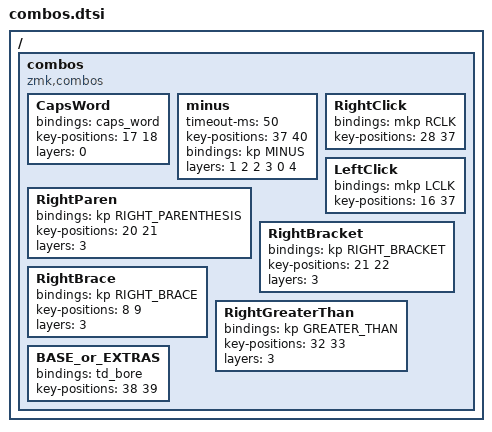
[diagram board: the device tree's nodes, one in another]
// ╭──────┬──────┬──────┬──────┬──────┬──────╮  ╭──────┬──────┬──────┬──────┬──────┬──────╮
//    00     01     02     03    04      05        06     07     08     09     10     11
// ├──────┼──────┼──────┼──────┼──────┼──────┤  ├──────┼──────┼──────┼──────┼──────┼──────┤
//    12     13     14     15    16      17        18     19     20     21     22     23
// ├──────┼──────┼──────┼──────┼──────┼──────┤  ├──────┼──────┼──────┼──────┼──────┼──────┤
//    24     25     26     27    28      29        30     31     32     33     34     35
// ╰──────┴──────┴──────┼──────┼──────┼──────┤  ├──────┼──────┼──────┴──────┴──────┴──────╯
//                         36     37     38        39     40
//                      ╰──────┴──────┴──────╯  ╰──────┴──────╯

/ {
    combos {
        compatible = "zmk,combos";

        CapsWord {
            bindings = <&caps_word>;
            key-positions = <17 18>;
            layers = <0>;
        };

        minus {
            timeout-ms = <50>;
            key-positions = <37 40>; // KP: VB
            bindings = <&kp MINUS>;
            layers = <1 2 2 3 0 4>;
        };

        RightClick {
            bindings = <&mkp RCLK>;
            key-positions = <28 37>;
        };

        LeftClick {
            bindings = <&mkp LCLK>;
            key-positions = <16 37>;
        };

        RightParen {
            bindings = <&kp RIGHT_PARENTHESIS>;
            key-positions = <20 21>;
            layers = <3>;
        };

        RightBracket {
            bindings = <&kp RIGHT_BRACKET>;
            key-positions = <21 22>;
            layers = <3>;
        };

        RightBrace {
            bindings = <&kp RIGHT_BRACE>;
            key-positions = <8 9>;
            layers = <3>;
        };

        RightGreaterThan {
            bindings = <&kp GREATER_THAN>;
            key-positions = <32 33>;
            layers = <3>;
        };

        BASE_or_EXTRAS {
            bindings = <&td_bore>;
            key-positions = <38 39>;
        };

        // GameLayer {
        //     bindings = <&tog 4>;
        //     key-positions = <8 9>;
        // };

        // PhotoLayer {
        //     bindings = <&tog 5>;
        //     key-positions = <2 3>;
        // };
    };
};
